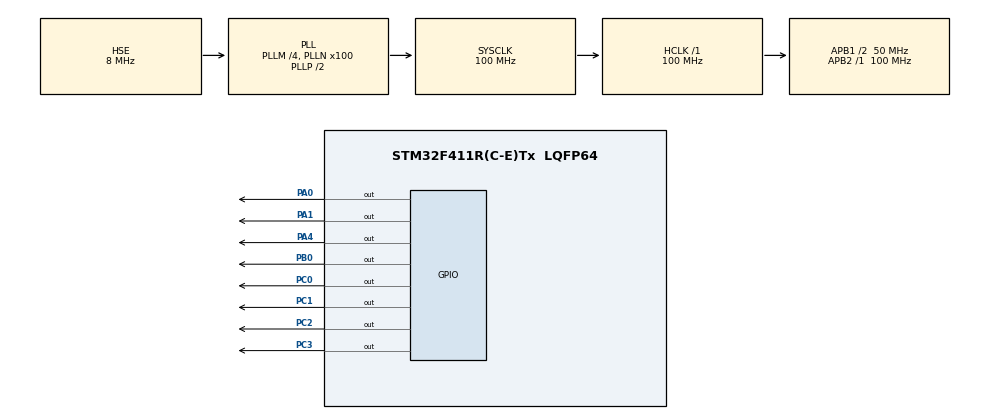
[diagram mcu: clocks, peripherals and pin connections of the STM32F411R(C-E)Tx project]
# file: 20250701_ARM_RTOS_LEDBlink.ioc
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FREERTOS.Tasks01=defaultTask,0,128,StartDefaultTask,Default,NULL,Dynamic,NULL,NULL;myled1,0,128,LedTask01,Default,NULL,Dynamic,NULL,NULL;myled2,0,128,LedTask02,Default,NULL,Dynamic,NULL,NULL;myled3,-1,128,LedTask03,Default,NULL,Dynamic,NULL,NULL
FREERTOS.configUSE_NEWLIB_REENTRANT=1
Mcu.Family=STM32F4
Mcu.Name=STM32F411R(C-E)Tx
Mcu.Package=LQFP64
NVIC.PriorityGroup=NVIC_PRIORITYGROUP_4
NVIC.TIM1_TRG_COM_TIM11_IRQn=true\:15\:0\:false\:false\:true\:false\:false\:true\:true
NVIC.TimeBase=TIM1_TRG_COM_TIM11_IRQn
NVIC.TimeBaseIP=TIM11
PA0-WKUP.Signal=GPIO_Output
PA1.Signal=GPIO_Output
PA13.Mode=Serial_Wire
PA13.Signal=SYS_JTMS-SWDIO
PA14.Mode=Serial_Wire
PA14.Signal=SYS_JTCK-SWCLK
PA4.Signal=GPIO_Output
PB0.Signal=GPIO_Output
PC0.Signal=GPIO_Output
PC1.Signal=GPIO_Output
PC2.Signal=GPIO_Output
PC3.Signal=GPIO_Output
PH0\ -\ OSC_IN.Mode=HSE-External-Oscillator
PH0\ -\ OSC_IN.Signal=RCC_OSC_IN
PH1\ -\ OSC_OUT.Mode=HSE-External-Oscillator
PH1\ -\ OSC_OUT.Signal=RCC_OSC_OUT
ProjectManager.HeapSize=0x200
ProjectManager.StackSize=0x400
ProjectManager.TargetToolchain=STM32CubeIDE
RCC.48MHZClocksFreq_Value=50000000
RCC.AHBFreq_Value=100000000
RCC.APB1CLKDivider=RCC_HCLK_DIV2
RCC.APB1Freq_Value=50000000
RCC.APB1TimFreq_Value=100000000
RCC.APB2Freq_Value=100000000
RCC.APB2TimFreq_Value=100000000
RCC.CortexFreq_Value=100000000
RCC.HCLKFreq_Value=100000000
RCC.HSE_VALUE=8000000
RCC.HSI_VALUE=16000000
RCC.LSE_VALUE=32768
RCC.PLLM=4
RCC.PLLN=100
RCC.PLLSourceVirtual=RCC_PLLSOURCE_HSE
RCC.SYSCLKFreq_VALUE=100000000
RCC.SYSCLKSource=RCC_SYSCLKSOURCE_PLLCLK
RCC.VCOOutputFreq_Value=200000000
VP_FREERTOS_VS_CMSIS_V1.Mode=CMSIS_V1
VP_SYS_VS_tim11.Mode=TIM11
board=custom

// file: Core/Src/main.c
/* USER CODE BEGIN Header */
/**
  ******************************************************************************
  * @file           : main.c
  * @brief          : Main program body
  ******************************************************************************
  * @attention
  *
  * Copyright (c) 2025 STMicroelectronics.
  * All rights reserved.
  *
  * This software is licensed under terms that can be found in the LICENSE file
  * in the root directory of this software component.
  * If no LICENSE file comes with this software, it is provided AS-IS.
  *
  ******************************************************************************
  */
/* USER CODE END Header */
#include "main.h"
#include "cmsis_os.h"

osThreadId defaultTaskHandle;
osThreadId myled1Handle;
osThreadId myled2Handle;
osThreadId myled3Handle;

void SystemClock_Config(void);
static void MX_GPIO_Init(void);
void StartDefaultTask(void const * argument);
void LedTask01(void const * argument);
void LedTask02(void const * argument);
void LedTask03(void const * argument);

int main(void)
{

  /* MCU Configuration--------------------------------------------------------*/

  /* Reset of all peripherals, Initializes the Flash interface and the Systick. */
  HAL_Init();

  /* Configure the system clock */
  SystemClock_Config();

  /* Initialize all configured peripherals */
  MX_GPIO_Init();

  /* Create the thread(s) */
  /* definition and creation of defaultTask */
  osThreadDef(defaultTask, StartDefaultTask, osPriorityNormal, 0, 128);
  defaultTaskHandle = osThreadCreate(osThread(defaultTask), NULL);

  /* definition and creation of myled1 */
  osThreadDef(myled1, LedTask01, osPriorityNormal, 0, 128);
  myled1Handle = osThreadCreate(osThread(myled1), NULL);

  /* definition and creation of myled2 */
  osThreadDef(myled2, LedTask02, osPriorityNormal, 0, 128);
  myled2Handle = osThreadCreate(osThread(myled2), NULL);

  /* definition and creation of myled3 */
  osThreadDef(myled3, LedTask03, osPriorityBelowNormal, 0, 128);
  myled3Handle = osThreadCreate(osThread(myled3), NULL);

  /* Start scheduler */
  osKernelStart();

  /* We should never get here as control is now taken by the scheduler */

  /* Infinite loop */
  while (1)
  {

  }
}

void SystemClock_Config(void)
{
  RCC_OscInitTypeDef RCC_OscInitStruct = {0};
  RCC_ClkInitTypeDef RCC_ClkInitStruct = {0};

  /** Configure the main internal regulator output voltage
  */
  __HAL_RCC_PWR_CLK_ENABLE();
  __HAL_PWR_VOLTAGESCALING_CONFIG(PWR_REGULATOR_VOLTAGE_SCALE1);

  /** Initializes the RCC Oscillators according to the specified parameters
  * in the RCC_OscInitTypeDef structure.
  */
  RCC_OscInitStruct.OscillatorType = RCC_OSCILLATORTYPE_HSE;
  RCC_OscInitStruct.HSEState = RCC_HSE_ON;
  RCC_OscInitStruct.PLL.PLLState = RCC_PLL_ON;
  RCC_OscInitStruct.PLL.PLLSource = RCC_PLLSOURCE_HSE;
  RCC_OscInitStruct.PLL.PLLM = 4;
  RCC_OscInitStruct.PLL.PLLN = 100;
  RCC_OscInitStruct.PLL.PLLP = RCC_PLLP_DIV2;
  RCC_OscInitStruct.PLL.PLLQ = 4;
  if (HAL_RCC_OscConfig(&RCC_OscInitStruct) != HAL_OK)
  {
    Error_Handler();
  }

  /** Initializes the CPU, AHB and APB buses clocks
  */
  RCC_ClkInitStruct.ClockType = RCC_CLOCKTYPE_HCLK|RCC_CLOCKTYPE_SYSCLK
                              |RCC_CLOCKTYPE_PCLK1|RCC_CLOCKTYPE_PCLK2;
  RCC_ClkInitStruct.SYSCLKSource = RCC_SYSCLKSOURCE_PLLCLK;
  RCC_ClkInitStruct.AHBCLKDivider = RCC_SYSCLK_DIV1;
  RCC_ClkInitStruct.APB1CLKDivider = RCC_HCLK_DIV2;
  RCC_ClkInitStruct.APB2CLKDivider = RCC_HCLK_DIV1;

  if (HAL_RCC_ClockConfig(&RCC_ClkInitStruct, FLASH_LATENCY_3) != HAL_OK)
  {
    Error_Handler();
  }
}

static void MX_GPIO_Init(void)
{
  GPIO_InitTypeDef GPIO_InitStruct = {0};

  /* GPIO Ports Clock Enable */
  __HAL_RCC_GPIOH_CLK_ENABLE();
  __HAL_RCC_GPIOC_CLK_ENABLE();
  __HAL_RCC_GPIOA_CLK_ENABLE();
  __HAL_RCC_GPIOB_CLK_ENABLE();

  /*Configure GPIO pin Output Level */
  HAL_GPIO_WritePin(GPIOC, GPIO_PIN_0|GPIO_PIN_1|GPIO_PIN_2|GPIO_PIN_3, GPIO_PIN_RESET);

  /*Configure GPIO pin Output Level */
  HAL_GPIO_WritePin(GPIOA, GPIO_PIN_0|GPIO_PIN_1|GPIO_PIN_4, GPIO_PIN_RESET);

  /*Configure GPIO pin Output Level */
  HAL_GPIO_WritePin(GPIOB, GPIO_PIN_0, GPIO_PIN_RESET);

  /*Configure GPIO pins : PC0 PC1 PC2 PC3 */
  GPIO_InitStruct.Pin = GPIO_PIN_0|GPIO_PIN_1|GPIO_PIN_2|GPIO_PIN_3;
  GPIO_InitStruct.Mode = GPIO_MODE_OUTPUT_PP;
  GPIO_InitStruct.Pull = GPIO_NOPULL;
  GPIO_InitStruct.Speed = GPIO_SPEED_FREQ_LOW;
  HAL_GPIO_Init(GPIOC, &GPIO_InitStruct);

  /*Configure GPIO pins : PA0 PA1 PA4 */
  GPIO_InitStruct.Pin = GPIO_PIN_0|GPIO_PIN_1|GPIO_PIN_4;
  GPIO_InitStruct.Mode = GPIO_MODE_OUTPUT_PP;
  GPIO_InitStruct.Pull = GPIO_NOPULL;
  GPIO_InitStruct.Speed = GPIO_SPEED_FREQ_LOW;
  HAL_GPIO_Init(GPIOA, &GPIO_InitStruct);

  /*Configure GPIO pin : PB0 */
  GPIO_InitStruct.Pin = GPIO_PIN_0;
  GPIO_InitStruct.Mode = GPIO_MODE_OUTPUT_PP;
  GPIO_InitStruct.Pull = GPIO_NOPULL;
  GPIO_InitStruct.Speed = GPIO_SPEED_FREQ_LOW;
  HAL_GPIO_Init(GPIOB, &GPIO_InitStruct);

}

void StartDefaultTask(void const * argument)
{
  for(;;)
  {
    osDelay(1);
  }
}

void LedTask01(void const * argument)
{
  /* USER CODE BEGIN LedTask01 */
  /* Infinite loop */
  for(;;)
  {
	  HAL_GPIO_TogglePin(GPIOA, GPIO_PIN_0);
    osDelay(200);
  }
  /* USER CODE END LedTask01 */
}

void LedTask02(void const * argument)
{
  /* USER CODE BEGIN LedTask02 */
  /* Infinite loop */
  for(;;)
  {
	  HAL_GPIO_TogglePin(GPIOA, GPIO_PIN_1);
    osDelay(500);
  }
  /* USER CODE END LedTask02 */

}

void LedTask03(void const * argument)
{
  /* USER CODE BEGIN LedTask03 */
  /* Infinite loop */
  for(;;)
  {
	 HAL_GPIO_TogglePin(GPIOA, GPIO_PIN_4);
     osDelay(1000);

  }
  /* USER CODE END LedTask03 */
}

void HAL_TIM_PeriodElapsedCallback(TIM_HandleTypeDef *htim)
{
  if (htim->Instance == TIM11)
  {
    HAL_IncTick();
  }
}

void Error_Handler(void)
{
  __disable_irq();
  while (1)
  {
  }
}
